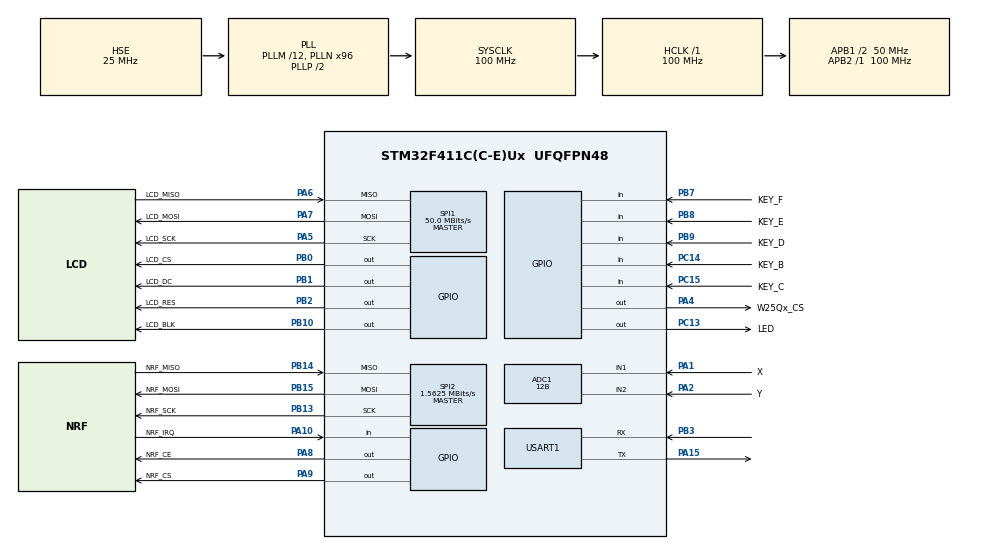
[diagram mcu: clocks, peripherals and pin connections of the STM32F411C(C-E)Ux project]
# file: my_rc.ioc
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ADC1.Channel-0\#ChannelRegularConversion=ADC_CHANNEL_1
ADC1.Channel-5\#ChannelRegularConversion=ADC_CHANNEL_2
ADC1.ClockPrescaler=ADC_CLOCK_SYNC_PCLK_DIV4
ADC1.ContinuousConvMode=ENABLE
ADC1.DMAContinuousRequests=ENABLE
ADC1.DiscontinuousConvMode=DISABLE
ADC1.NbrOfConversion=2
ADC1.NbrOfConversionFlag=1
ADC1.Rank-0\#ChannelRegularConversion=1
ADC1.Rank-5\#ChannelRegularConversion=2
ADC1.Resolution=ADC_RESOLUTION_12B
ADC1.SamplingTime-0\#ChannelRegularConversion=ADC_SAMPLETIME_3CYCLES
ADC1.SamplingTime-5\#ChannelRegularConversion=ADC_SAMPLETIME_3CYCLES
ADC1.ScanConvMode=ENABLE
ADC1.master=1
Dma.ADC1.0.Direction=DMA_PERIPH_TO_MEMORY
Dma.ADC1.0.FIFOMode=DMA_FIFOMODE_DISABLE
Dma.ADC1.0.Instance=DMA2_Stream0
Dma.ADC1.0.MemDataAlignment=DMA_MDATAALIGN_HALFWORD
Dma.ADC1.0.MemInc=DMA_MINC_ENABLE
Dma.ADC1.0.Mode=DMA_CIRCULAR
Dma.ADC1.0.PeriphDataAlignment=DMA_PDATAALIGN_HALFWORD
Dma.ADC1.0.PeriphInc=DMA_PINC_DISABLE
Dma.ADC1.0.Priority=DMA_PRIORITY_MEDIUM
Dma.Request0=ADC1
Dma.Request1=SPI1_TX
Dma.Request2=USART1_RX
Dma.Request3=USART1_TX
Dma.SPI1_TX.1.Direction=DMA_MEMORY_TO_PERIPH
Dma.SPI1_TX.1.FIFOMode=DMA_FIFOMODE_DISABLE
Dma.SPI1_TX.1.Instance=DMA2_Stream5
Dma.SPI1_TX.1.MemDataAlignment=DMA_MDATAALIGN_BYTE
Dma.SPI1_TX.1.MemInc=DMA_MINC_ENABLE
Dma.SPI1_TX.1.Mode=DMA_NORMAL
Dma.SPI1_TX.1.PeriphDataAlignment=DMA_PDATAALIGN_BYTE
Dma.SPI1_TX.1.PeriphInc=DMA_PINC_DISABLE
Dma.SPI1_TX.1.Priority=DMA_PRIORITY_MEDIUM
Dma.USART1_RX.2.Direction=DMA_PERIPH_TO_MEMORY
Dma.USART1_RX.2.FIFOMode=DMA_FIFOMODE_DISABLE
Dma.USART1_RX.2.Instance=DMA2_Stream2
Dma.USART1_RX.2.MemDataAlignment=DMA_MDATAALIGN_BYTE
Dma.USART1_RX.2.MemInc=DMA_MINC_ENABLE
Dma.USART1_RX.2.Mode=DMA_NORMAL
Dma.USART1_RX.2.PeriphDataAlignment=DMA_PDATAALIGN_BYTE
Dma.USART1_RX.2.PeriphInc=DMA_PINC_DISABLE
Dma.USART1_RX.2.Priority=DMA_PRIORITY_HIGH
Dma.USART1_TX.3.Direction=DMA_MEMORY_TO_PERIPH
Dma.USART1_TX.3.FIFOMode=DMA_FIFOMODE_DISABLE
Dma.USART1_TX.3.Instance=DMA2_Stream7
Dma.USART1_TX.3.MemDataAlignment=DMA_MDATAALIGN_BYTE
Dma.USART1_TX.3.MemInc=DMA_MINC_ENABLE
Dma.USART1_TX.3.Mode=DMA_NORMAL
Dma.USART1_TX.3.PeriphDataAlignment=DMA_PDATAALIGN_BYTE
Dma.USART1_TX.3.PeriphInc=DMA_PINC_DISABLE
Dma.USART1_TX.3.Priority=DMA_PRIORITY_MEDIUM
Mcu.Family=STM32F4
Mcu.Name=STM32F411C(C-E)Ux
Mcu.Package=UFQFPN48
NVIC.DMA2_Stream0_IRQn=true\:0\:0\:false\:false\:true\:false\:true\:true
NVIC.DMA2_Stream2_IRQn=true\:0\:0\:false\:false\:true\:false\:true\:true
NVIC.DMA2_Stream5_IRQn=true\:0\:0\:false\:false\:true\:false\:true\:true
NVIC.DMA2_Stream7_IRQn=true\:0\:0\:false\:false\:true\:false\:true\:true
NVIC.PriorityGroup=NVIC_PRIORITYGROUP_4
NVIC.TIM1_UP_TIM10_IRQn=true\:0\:0\:false\:false\:true\:true\:true\:true
NVIC.USART1_IRQn=true\:0\:0\:false\:false\:true\:true\:true\:true
PA1.GPIO_Label=X
PA1.Signal=ADCx_IN1
PA10.GPIO_Label=NRF_IRQ
PA10.GPIO_PuPd=GPIO_PULLUP
PA10.Signal=GPIO_Input
PA13.Mode=Serial_Wire
PA13.Signal=SYS_JTMS-SWDIO
PA14.Mode=Serial_Wire
PA14.Signal=SYS_JTCK-SWCLK
PA15.Mode=Asynchronous
PA15.Signal=USART1_TX
PA2.GPIO_Label=Y
PA2.Signal=ADCx_IN2
PA4.GPIO_Label=W25Qx_CS
PA4.GPIO_PuPd=GPIO_PULLUP
PA4.GPIO_Speed=GPIO_SPEED_FREQ_HIGH
PA4.PinState=GPIO_PIN_SET
PA4.Signal=GPIO_Output
PA5.GPIO_Label=LCD_SCK
PA5.Mode=Full_Duplex_Master
PA5.Signal=SPI1_SCK
PA6.GPIO_Label=LCD_MISO
PA6.Mode=Full_Duplex_Master
PA6.Signal=SPI1_MISO
PA7.GPIO_Label=LCD_MOSI
PA7.Mode=Full_Duplex_Master
PA7.Signal=SPI1_MOSI
PA8.GPIO_Label=NRF_CE
PA8.GPIO_PuPd=GPIO_PULLUP
PA8.GPIO_Speed=GPIO_SPEED_FREQ_HIGH
PA8.Signal=GPIO_Output
PA9.GPIO_Label=NRF_CS
PA9.GPIO_PuPd=GPIO_PULLUP
PA9.GPIO_Speed=GPIO_SPEED_FREQ_HIGH
PA9.PinState=GPIO_PIN_SET
PA9.Signal=GPIO_Output
PB0.GPIO_Label=LCD_CS
PB0.GPIO_PuPd=GPIO_PULLUP
PB0.GPIO_Speed=GPIO_SPEED_FREQ_VERY_HIGH
PB0.PinState=GPIO_PIN_SET
PB0.Signal=GPIO_Output
PB1.GPIO_Label=LCD_DC
PB1.GPIO_PuPd=GPIO_PULLUP
PB1.GPIO_Speed=GPIO_SPEED_FREQ_VERY_HIGH
PB1.PinState=GPIO_PIN_SET
PB1.Signal=GPIO_Output
PB10.GPIO_Label=LCD_BLK
PB10.GPIO_ModeDefaultOutputPP=GPIO_MODE_OUTPUT_PP
PB10.GPIO_PuPd=GPIO_PULLUP
PB10.GPIO_Speed=GPIO_SPEED_FREQ_HIGH
PB10.PinState=GPIO_PIN_SET
PB10.Signal=GPIO_Output
PB13.GPIO_Label=NRF_SCK
PB13.Mode=Full_Duplex_Master
PB13.Signal=SPI2_SCK
PB14.GPIO_Label=NRF_MISO
PB14.Mode=Full_Duplex_Master
PB14.Signal=SPI2_MISO
PB15.GPIO_Label=NRF_MOSI
PB15.Mode=Full_Duplex_Master
PB15.Signal=SPI2_MOSI
PB2.GPIO_Label=LCD_RES
PB2.GPIO_PuPd=GPIO_PULLUP
PB2.GPIO_Speed=GPIO_SPEED_FREQ_HIGH
PB2.PinState=GPIO_PIN_SET
PB2.Signal=GPIO_Output
PB3.Mode=Asynchronous
PB3.Signal=USART1_RX
PB7.GPIO_Label=KEY_F
PB7.Signal=GPIO_Input
PB8.GPIO_Label=KEY_E
PB8.Signal=GPIO_Input
PB9.GPIO_Label=KEY_D
PB9.Signal=GPIO_Input
PC13-ANTI_TAMP.GPIO_Label=LED
PC13-ANTI_TAMP.PinState=GPIO_PIN_SET
PC13-ANTI_TAMP.Signal=GPIO_Output
PC14-OSC32_IN.GPIO_Label=KEY_B
PC14-OSC32_IN.Signal=GPIO_Input
PC15-OSC32_OUT.GPIO_Label=KEY_C
PC15-OSC32_OUT.Signal=GPIO_Input
PH0\ -\ OSC_IN.Mode=HSE-External-Oscillator
PH0\ -\ OSC_IN.Signal=RCC_OSC_IN
PH1\ -\ OSC_OUT.Mode=HSE-External-Oscillator
PH1\ -\ OSC_OUT.Signal=RCC_OSC_OUT
ProjectManager.HeapSize=0x200
ProjectManager.StackSize=0x400
ProjectManager.TargetToolchain=MDK-ARM V5.32
RCC.48MHZClocksFreq_Value=40000000
RCC.AHBFreq_Value=100000000
RCC.APB1CLKDivider=RCC_HCLK_DIV2
RCC.APB1Freq_Value=50000000
RCC.APB1TimFreq_Value=100000000
RCC.APB2Freq_Value=100000000
RCC.APB2TimFreq_Value=100000000
RCC.CortexFreq_Value=100000000
RCC.HCLKFreq_Value=100000000
RCC.HSE_VALUE=25000000
RCC.HSI_VALUE=16000000
RCC.LSE_VALUE=32768
RCC.PLLM=12
RCC.PLLN=96
RCC.PLLQ=5
RCC.PLLSourceVirtual=RCC_PLLSOURCE_HSE
RCC.SYSCLKFreq_VALUE=100000000
RCC.SYSCLKSource=RCC_SYSCLKSOURCE_PLLCLK
RCC.VCOOutputFreq_Value=200000000
SH.ADCx_IN1.0=ADC1_IN1,IN1
SH.ADCx_IN2.0=ADC1_IN2,IN2
SPI1.BaudRatePrescaler=SPI_BAUDRATEPRESCALER_2
SPI1.CLKPhase=SPI_PHASE_2EDGE
SPI1.CLKPolarity=SPI_POLARITY_HIGH
SPI1.CalculateBaudRate=50.0 MBits/s
SPI1.DataSize=SPI_DATASIZE_8BIT
SPI1.Direction=SPI_DIRECTION_2LINES
SPI1.Mode=SPI_MODE_MASTER
SPI1.VirtualType=VM_MASTER
SPI2.BaudRatePrescaler=SPI_BAUDRATEPRESCALER_32
SPI2.CalculateBaudRate=1.5625 MBits/s
SPI2.Direction=SPI_DIRECTION_2LINES
SPI2.Mode=SPI_MODE_MASTER
SPI2.VirtualType=VM_MASTER
TIM10.Prescaler=59
USART1.VirtualMode=VM_ASYNC
VP_TIM10_VS_ClockSourceINT.Mode=Enable_Timer
board=custom

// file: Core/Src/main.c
/* USER CODE BEGIN Header */
/**
  ******************************************************************************
  * @file           : main.c
  * @brief          : Main program body
  ******************************************************************************
  * @attention
  *
  * Copyright (c) 2023 STMicroelectronics.
  * All rights reserved.
  *
  * This software is licensed under terms that can be found in the LICENSE file
  * in the root directory of this software component.
  * If no LICENSE file comes with this software, it is provided AS-IS.
  *
  ******************************************************************************
  */
/* USER CODE END Header */
#include "main.h"

/* USER CODE BEGIN Includes */
#include "system_start.h"
/* USER CODE END Includes */

void SystemClock_Config(void);
static void MX_GPIO_Init(void);
static void MX_DMA_Init(void);
static void MX_TIM10_Init(void);
static void MX_ADC1_Init(void);
static void MX_SPI1_Init(void);
static void MX_SPI2_Init(void);
static void MX_USART1_UART_Init(void);

int main(void)
{

  /* MCU Configuration--------------------------------------------------------*/

  /* Reset of all peripherals, Initializes the Flash interface and the Systick. */
  HAL_Init();

  /* Configure the system clock */
  SystemClock_Config();

  /* Initialize all configured peripherals */
  MX_GPIO_Init();
  MX_DMA_Init();
  MX_TIM10_Init();
  MX_ADC1_Init();
  MX_SPI1_Init();
  MX_SPI2_Init();
  MX_USART1_UART_Init();
  /* USER CODE BEGIN 2 */
	System_Init();
  /* USER CODE END 2 */

  /* Infinite loop */
  /* USER CODE BEGIN WHILE */
  while (1)
  {
		System_Loop();
    /* USER CODE END WHILE */

  }
}

void SystemClock_Config(void)
{
  RCC_OscInitTypeDef RCC_OscInitStruct = {0};
  RCC_ClkInitTypeDef RCC_ClkInitStruct = {0};

  /** Configure the main internal regulator output voltage
  */
  __HAL_RCC_PWR_CLK_ENABLE();
  __HAL_PWR_VOLTAGESCALING_CONFIG(PWR_REGULATOR_VOLTAGE_SCALE1);

  /** Initializes the RCC Oscillators according to the specified parameters
  * in the RCC_OscInitTypeDef structure.
  */
  RCC_OscInitStruct.OscillatorType = RCC_OSCILLATORTYPE_HSE;
  RCC_OscInitStruct.HSEState = RCC_HSE_ON;
  RCC_OscInitStruct.PLL.PLLState = RCC_PLL_ON;
  RCC_OscInitStruct.PLL.PLLSource = RCC_PLLSOURCE_HSE;
  RCC_OscInitStruct.PLL.PLLM = 12;
  RCC_OscInitStruct.PLL.PLLN = 96;
  RCC_OscInitStruct.PLL.PLLP = RCC_PLLP_DIV2;
  RCC_OscInitStruct.PLL.PLLQ = 5;
  if (HAL_RCC_OscConfig(&RCC_OscInitStruct) != HAL_OK)
  {
    Error_Handler();
  }

  /** Initializes the CPU, AHB and APB buses clocks
  */
  RCC_ClkInitStruct.ClockType = RCC_CLOCKTYPE_HCLK|RCC_CLOCKTYPE_SYSCLK
                              |RCC_CLOCKTYPE_PCLK1|RCC_CLOCKTYPE_PCLK2;
  RCC_ClkInitStruct.SYSCLKSource = RCC_SYSCLKSOURCE_PLLCLK;
  RCC_ClkInitStruct.AHBCLKDivider = RCC_SYSCLK_DIV1;
  RCC_ClkInitStruct.APB1CLKDivider = RCC_HCLK_DIV2;
  RCC_ClkInitStruct.APB2CLKDivider = RCC_HCLK_DIV1;

  if (HAL_RCC_ClockConfig(&RCC_ClkInitStruct, FLASH_LATENCY_3) != HAL_OK)
  {
    Error_Handler();
  }
}

static void MX_ADC1_Init(void)
{

  LL_ADC_InitTypeDef ADC_InitStruct = {0};
  LL_ADC_REG_InitTypeDef ADC_REG_InitStruct = {0};
  LL_ADC_CommonInitTypeDef ADC_CommonInitStruct = {0};

  LL_GPIO_InitTypeDef GPIO_InitStruct = {0};

  /* Peripheral clock enable */
  LL_APB2_GRP1_EnableClock(LL_APB2_GRP1_PERIPH_ADC1);

  LL_AHB1_GRP1_EnableClock(LL_AHB1_GRP1_PERIPH_GPIOA);
  /**ADC1 GPIO Configuration
  PA1   ------> ADC1_IN1
  PA2   ------> ADC1_IN2
  */
  GPIO_InitStruct.Pin = LL_GPIO_PIN_1|LL_GPIO_PIN_2;
  GPIO_InitStruct.Mode = LL_GPIO_MODE_ANALOG;
  GPIO_InitStruct.Pull = LL_GPIO_PULL_NO;
  LL_GPIO_Init(GPIOA, &GPIO_InitStruct);

  /* ADC1 DMA Init */

  /* ADC1 Init */
  LL_DMA_SetChannelSelection(DMA2, LL_DMA_STREAM_0, LL_DMA_CHANNEL_0);

  LL_DMA_SetDataTransferDirection(DMA2, LL_DMA_STREAM_0, LL_DMA_DIRECTION_PERIPH_TO_MEMORY);

  LL_DMA_SetStreamPriorityLevel(DMA2, LL_DMA_STREAM_0, LL_DMA_PRIORITY_MEDIUM);

  LL_DMA_SetMode(DMA2, LL_DMA_STREAM_0, LL_DMA_MODE_CIRCULAR);

  LL_DMA_SetPeriphIncMode(DMA2, LL_DMA_STREAM_0, LL_DMA_PERIPH_NOINCREMENT);

  LL_DMA_SetMemoryIncMode(DMA2, LL_DMA_STREAM_0, LL_DMA_MEMORY_INCREMENT);

  LL_DMA_SetPeriphSize(DMA2, LL_DMA_STREAM_0, LL_DMA_PDATAALIGN_HALFWORD);

  LL_DMA_SetMemorySize(DMA2, LL_DMA_STREAM_0, LL_DMA_MDATAALIGN_HALFWORD);

  LL_DMA_DisableFifoMode(DMA2, LL_DMA_STREAM_0);

  /** Common config
  */
  ADC_InitStruct.Resolution = LL_ADC_RESOLUTION_12B;
  ADC_InitStruct.DataAlignment = LL_ADC_DATA_ALIGN_RIGHT;
  ADC_InitStruct.SequencersScanMode = LL_ADC_SEQ_SCAN_ENABLE;
  LL_ADC_Init(ADC1, &ADC_InitStruct);
  ADC_REG_InitStruct.TriggerSource = LL_ADC_REG_TRIG_SOFTWARE;
  ADC_REG_InitStruct.SequencerLength = LL_ADC_REG_SEQ_SCAN_ENABLE_2RANKS;
  ADC_REG_InitStruct.SequencerDiscont = LL_ADC_REG_SEQ_DISCONT_DISABLE;
  ADC_REG_InitStruct.ContinuousMode = LL_ADC_REG_CONV_CONTINUOUS;
  ADC_REG_InitStruct.DMATransfer = LL_ADC_REG_DMA_TRANSFER_UNLIMITED;
  LL_ADC_REG_Init(ADC1, &ADC_REG_InitStruct);
  LL_ADC_REG_SetFlagEndOfConversion(ADC1, LL_ADC_REG_FLAG_EOC_UNITARY_CONV);
  ADC_CommonInitStruct.CommonClock = LL_ADC_CLOCK_SYNC_PCLK_DIV4;
  LL_ADC_CommonInit(__LL_ADC_COMMON_INSTANCE(ADC1), &ADC_CommonInitStruct);

  /** Configure Regular Channel
  */
  LL_ADC_REG_SetSequencerRanks(ADC1, LL_ADC_REG_RANK_1, LL_ADC_CHANNEL_1);
  LL_ADC_SetChannelSamplingTime(ADC1, LL_ADC_CHANNEL_1, LL_ADC_SAMPLINGTIME_3CYCLES);

  /** Configure Regular Channel
  */
  LL_ADC_REG_SetSequencerRanks(ADC1, LL_ADC_REG_RANK_2, LL_ADC_CHANNEL_2);
  LL_ADC_SetChannelSamplingTime(ADC1, LL_ADC_CHANNEL_2, LL_ADC_SAMPLINGTIME_3CYCLES);

}

static void MX_SPI1_Init(void)
{

  LL_SPI_InitTypeDef SPI_InitStruct = {0};

  LL_GPIO_InitTypeDef GPIO_InitStruct = {0};

  /* Peripheral clock enable */
  LL_APB2_GRP1_EnableClock(LL_APB2_GRP1_PERIPH_SPI1);

  LL_AHB1_GRP1_EnableClock(LL_AHB1_GRP1_PERIPH_GPIOA);
  /**SPI1 GPIO Configuration
  PA5   ------> SPI1_SCK
  PA6   ------> SPI1_MISO
  PA7   ------> SPI1_MOSI
  */
  GPIO_InitStruct.Pin = LL_GPIO_PIN_5|LL_GPIO_PIN_6|LL_GPIO_PIN_7;
  GPIO_InitStruct.Mode = LL_GPIO_MODE_ALTERNATE;
  GPIO_InitStruct.Speed = LL_GPIO_SPEED_FREQ_VERY_HIGH;
  GPIO_InitStruct.OutputType = LL_GPIO_OUTPUT_PUSHPULL;
  GPIO_InitStruct.Pull = LL_GPIO_PULL_NO;
  GPIO_InitStruct.Alternate = LL_GPIO_AF_5;
  LL_GPIO_Init(GPIOA, &GPIO_InitStruct);

  /* SPI1 DMA Init */

  /* SPI1_TX Init */
  LL_DMA_SetChannelSelection(DMA2, LL_DMA_STREAM_5, LL_DMA_CHANNEL_3);

  LL_DMA_SetDataTransferDirection(DMA2, LL_DMA_STREAM_5, LL_DMA_DIRECTION_MEMORY_TO_PERIPH);

  LL_DMA_SetStreamPriorityLevel(DMA2, LL_DMA_STREAM_5, LL_DMA_PRIORITY_MEDIUM);

  LL_DMA_SetMode(DMA2, LL_DMA_STREAM_5, LL_DMA_MODE_NORMAL);

  LL_DMA_SetPeriphIncMode(DMA2, LL_DMA_STREAM_5, LL_DMA_PERIPH_NOINCREMENT);

  LL_DMA_SetMemoryIncMode(DMA2, LL_DMA_STREAM_5, LL_DMA_MEMORY_INCREMENT);

  LL_DMA_SetPeriphSize(DMA2, LL_DMA_STREAM_5, LL_DMA_PDATAALIGN_BYTE);

  LL_DMA_SetMemorySize(DMA2, LL_DMA_STREAM_5, LL_DMA_MDATAALIGN_BYTE);

  LL_DMA_DisableFifoMode(DMA2, LL_DMA_STREAM_5);

  /* SPI1 parameter configuration*/
  SPI_InitStruct.TransferDirection = LL_SPI_FULL_DUPLEX;
  SPI_InitStruct.Mode = LL_SPI_MODE_MASTER;
  SPI_InitStruct.DataWidth = LL_SPI_DATAWIDTH_8BIT;
  SPI_InitStruct.ClockPolarity = LL_SPI_POLARITY_HIGH;
  SPI_InitStruct.ClockPhase = LL_SPI_PHASE_2EDGE;
  SPI_InitStruct.NSS = LL_SPI_NSS_SOFT;
  SPI_InitStruct.BaudRate = LL_SPI_BAUDRATEPRESCALER_DIV2;
  SPI_InitStruct.BitOrder = LL_SPI_MSB_FIRST;
  SPI_InitStruct.CRCCalculation = LL_SPI_CRCCALCULATION_DISABLE;
  SPI_InitStruct.CRCPoly = 10;
  LL_SPI_Init(SPI1, &SPI_InitStruct);
  LL_SPI_SetStandard(SPI1, LL_SPI_PROTOCOL_MOTOROLA);

}

static void MX_SPI2_Init(void)
{

  LL_SPI_InitTypeDef SPI_InitStruct = {0};

  LL_GPIO_InitTypeDef GPIO_InitStruct = {0};

  /* Peripheral clock enable */
  LL_APB1_GRP1_EnableClock(LL_APB1_GRP1_PERIPH_SPI2);

  LL_AHB1_GRP1_EnableClock(LL_AHB1_GRP1_PERIPH_GPIOB);
  /**SPI2 GPIO Configuration
  PB13   ------> SPI2_SCK
  PB14   ------> SPI2_MISO
  PB15   ------> SPI2_MOSI
  */
  GPIO_InitStruct.Pin = LL_GPIO_PIN_13|LL_GPIO_PIN_14|LL_GPIO_PIN_15;
  GPIO_InitStruct.Mode = LL_GPIO_MODE_ALTERNATE;
  GPIO_InitStruct.Speed = LL_GPIO_SPEED_FREQ_VERY_HIGH;
  GPIO_InitStruct.OutputType = LL_GPIO_OUTPUT_PUSHPULL;
  GPIO_InitStruct.Pull = LL_GPIO_PULL_NO;
  GPIO_InitStruct.Alternate = LL_GPIO_AF_5;
  LL_GPIO_Init(GPIOB, &GPIO_InitStruct);

  /* SPI2 parameter configuration*/
  SPI_InitStruct.TransferDirection = LL_SPI_FULL_DUPLEX;
  SPI_InitStruct.Mode = LL_SPI_MODE_MASTER;
  SPI_InitStruct.DataWidth = LL_SPI_DATAWIDTH_8BIT;
  SPI_InitStruct.ClockPolarity = LL_SPI_POLARITY_LOW;
  SPI_InitStruct.ClockPhase = LL_SPI_PHASE_1EDGE;
  SPI_InitStruct.NSS = LL_SPI_NSS_SOFT;
  SPI_InitStruct.BaudRate = LL_SPI_BAUDRATEPRESCALER_DIV32;
  SPI_InitStruct.BitOrder = LL_SPI_MSB_FIRST;
  SPI_InitStruct.CRCCalculation = LL_SPI_CRCCALCULATION_DISABLE;
  SPI_InitStruct.CRCPoly = 10;
  LL_SPI_Init(SPI2, &SPI_InitStruct);
  LL_SPI_SetStandard(SPI2, LL_SPI_PROTOCOL_MOTOROLA);

}

static void MX_TIM10_Init(void)
{

  LL_TIM_InitTypeDef TIM_InitStruct = {0};

  /* Peripheral clock enable */
  LL_APB2_GRP1_EnableClock(LL_APB2_GRP1_PERIPH_TIM10);

  /* TIM10 interrupt Init */
  NVIC_SetPriority(TIM1_UP_TIM10_IRQn, NVIC_EncodePriority(NVIC_GetPriorityGrouping(),0, 0));
  NVIC_EnableIRQ(TIM1_UP_TIM10_IRQn);

  TIM_InitStruct.Prescaler = 59;
  TIM_InitStruct.CounterMode = LL_TIM_COUNTERMODE_UP;
  TIM_InitStruct.Autoreload = 65535;
  TIM_InitStruct.ClockDivision = LL_TIM_CLOCKDIVISION_DIV1;
  LL_TIM_Init(TIM10, &TIM_InitStruct);
  LL_TIM_DisableARRPreload(TIM10);

}

static void MX_USART1_UART_Init(void)
{

  LL_USART_InitTypeDef USART_InitStruct = {0};

  LL_GPIO_InitTypeDef GPIO_InitStruct = {0};

  /* Peripheral clock enable */
  LL_APB2_GRP1_EnableClock(LL_APB2_GRP1_PERIPH_USART1);

  LL_AHB1_GRP1_EnableClock(LL_AHB1_GRP1_PERIPH_GPIOA);
  LL_AHB1_GRP1_EnableClock(LL_AHB1_GRP1_PERIPH_GPIOB);
  /**USART1 GPIO Configuration
  PA15   ------> USART1_TX
  PB3   ------> USART1_RX
  */
  GPIO_InitStruct.Pin = LL_GPIO_PIN_15;
  GPIO_InitStruct.Mode = LL_GPIO_MODE_ALTERNATE;
  GPIO_InitStruct.Speed = LL_GPIO_SPEED_FREQ_VERY_HIGH;
  GPIO_InitStruct.OutputType = LL_GPIO_OUTPUT_PUSHPULL;
  GPIO_InitStruct.Pull = LL_GPIO_PULL_NO;
  GPIO_InitStruct.Alternate = LL_GPIO_AF_7;
  LL_GPIO_Init(GPIOA, &GPIO_InitStruct);

  GPIO_InitStruct.Pin = LL_GPIO_PIN_3;
  GPIO_InitStruct.Mode = LL_GPIO_MODE_ALTERNATE;
  GPIO_InitStruct.Speed = LL_GPIO_SPEED_FREQ_VERY_HIGH;
  GPIO_InitStruct.OutputType = LL_GPIO_OUTPUT_PUSHPULL;
  GPIO_InitStruct.Pull = LL_GPIO_PULL_NO;
  GPIO_InitStruct.Alternate = LL_GPIO_AF_7;
  LL_GPIO_Init(GPIOB, &GPIO_InitStruct);

  /* USART1 DMA Init */

  /* USART1_RX Init */
  LL_DMA_SetChannelSelection(DMA2, LL_DMA_STREAM_2, LL_DMA_CHANNEL_4);

  LL_DMA_SetDataTransferDirection(DMA2, LL_DMA_STREAM_2, LL_DMA_DIRECTION_PERIPH_TO_MEMORY);

  LL_DMA_SetStreamPriorityLevel(DMA2, LL_DMA_STREAM_2, LL_DMA_PRIORITY_HIGH);

  LL_DMA_SetMode(DMA2, LL_DMA_STREAM_2, LL_DMA_MODE_NORMAL);

  LL_DMA_SetPeriphIncMode(DMA2, LL_DMA_STREAM_2, LL_DMA_PERIPH_NOINCREMENT);

  LL_DMA_SetMemoryIncMode(DMA2, LL_DMA_STREAM_2, LL_DMA_MEMORY_INCREMENT);

  LL_DMA_SetPeriphSize(DMA2, LL_DMA_STREAM_2, LL_DMA_PDATAALIGN_BYTE);

  LL_DMA_SetMemorySize(DMA2, LL_DMA_STREAM_2, LL_DMA_MDATAALIGN_BYTE);

  LL_DMA_DisableFifoMode(DMA2, LL_DMA_STREAM_2);

  /* USART1_TX Init */
  LL_DMA_SetChannelSelection(DMA2, LL_DMA_STREAM_7, LL_DMA_CHANNEL_4);

  LL_DMA_SetDataTransferDirection(DMA2, LL_DMA_STREAM_7, LL_DMA_DIRECTION_MEMORY_TO_PERIPH);

  LL_DMA_SetStreamPriorityLevel(DMA2, LL_DMA_STREAM_7, LL_DMA_PRIORITY_MEDIUM);

  LL_DMA_SetMode(DMA2, LL_DMA_STREAM_7, LL_DMA_MODE_NORMAL);

  LL_DMA_SetPeriphIncMode(DMA2, LL_DMA_STREAM_7, LL_DMA_PERIPH_NOINCREMENT);

  LL_DMA_SetMemoryIncMode(DMA2, LL_DMA_STREAM_7, LL_DMA_MEMORY_INCREMENT);

  LL_DMA_SetPeriphSize(DMA2, LL_DMA_STREAM_7, LL_DMA_PDATAALIGN_BYTE);

  LL_DMA_SetMemorySize(DMA2, LL_DMA_STREAM_7, LL_DMA_MDATAALIGN_BYTE);

  LL_DMA_DisableFifoMode(DMA2, LL_DMA_STREAM_7);

  /* USART1 interrupt Init */
  NVIC_SetPriority(USART1_IRQn, NVIC_EncodePriority(NVIC_GetPriorityGrouping(),0, 0));
  NVIC_EnableIRQ(USART1_IRQn);

  USART_InitStruct.BaudRate = 115200;
  USART_InitStruct.DataWidth = LL_USART_DATAWIDTH_8B;
  USART_InitStruct.StopBits = LL_USART_STOPBITS_1;
  USART_InitStruct.Parity = LL_USART_PARITY_NONE;
  USART_InitStruct.TransferDirection = LL_USART_DIRECTION_TX_RX;
  USART_InitStruct.HardwareFlowControl = LL_USART_HWCONTROL_NONE;
  USART_InitStruct.OverSampling = LL_USART_OVERSAMPLING_16;
  LL_USART_Init(USART1, &USART_InitStruct);
  LL_USART_ConfigAsyncMode(USART1);
  LL_USART_Enable(USART1);

}

static void MX_DMA_Init(void)
{

  /* Init with LL driver */
  /* DMA controller clock enable */
  LL_AHB1_GRP1_EnableClock(LL_AHB1_GRP1_PERIPH_DMA2);

  /* DMA interrupt init */
  /* DMA2_Stream0_IRQn interrupt configuration */
  NVIC_SetPriority(DMA2_Stream0_IRQn, NVIC_EncodePriority(NVIC_GetPriorityGrouping(),0, 0));
  NVIC_EnableIRQ(DMA2_Stream0_IRQn);
  /* DMA2_Stream2_IRQn interrupt configuration */
  NVIC_SetPriority(DMA2_Stream2_IRQn, NVIC_EncodePriority(NVIC_GetPriorityGrouping(),0, 0));
  NVIC_EnableIRQ(DMA2_Stream2_IRQn);
  /* DMA2_Stream5_IRQn interrupt configuration */
  NVIC_SetPriority(DMA2_Stream5_IRQn, NVIC_EncodePriority(NVIC_GetPriorityGrouping(),0, 0));
  NVIC_EnableIRQ(DMA2_Stream5_IRQn);
  /* DMA2_Stream7_IRQn interrupt configuration */
  NVIC_SetPriority(DMA2_Stream7_IRQn, NVIC_EncodePriority(NVIC_GetPriorityGrouping(),0, 0));
  NVIC_EnableIRQ(DMA2_Stream7_IRQn);

}

static void MX_GPIO_Init(void)
{
  GPIO_InitTypeDef GPIO_InitStruct = {0};

  /* GPIO Ports Clock Enable */
  __HAL_RCC_GPIOC_CLK_ENABLE();
  __HAL_RCC_GPIOH_CLK_ENABLE();
  __HAL_RCC_GPIOA_CLK_ENABLE();
  __HAL_RCC_GPIOB_CLK_ENABLE();

  /*Configure GPIO pin Output Level */
  HAL_GPIO_WritePin(LED_GPIO_Port, LED_Pin, GPIO_PIN_SET);

  /*Configure GPIO pin Output Level */
  HAL_GPIO_WritePin(GPIOA, W25Qx_CS_Pin|NRF_CS_Pin, GPIO_PIN_SET);

  /*Configure GPIO pin Output Level */
  HAL_GPIO_WritePin(GPIOB, LCD_CS_Pin|LCD_DC_Pin|LCD_RES_Pin|LCD_BLK_Pin, GPIO_PIN_SET);

  /*Configure GPIO pin Output Level */
  HAL_GPIO_WritePin(NRF_CE_GPIO_Port, NRF_CE_Pin, GPIO_PIN_RESET);

  /*Configure GPIO pin : LED_Pin */
  GPIO_InitStruct.Pin = LED_Pin;
  GPIO_InitStruct.Mode = GPIO_MODE_OUTPUT_PP;
  GPIO_InitStruct.Pull = GPIO_NOPULL;
  GPIO_InitStruct.Speed = GPIO_SPEED_FREQ_LOW;
  HAL_GPIO_Init(LED_GPIO_Port, &GPIO_InitStruct);

  /*Configure GPIO pins : KEY_B_Pin KEY_C_Pin */
  GPIO_InitStruct.Pin = KEY_B_Pin|KEY_C_Pin;
  GPIO_InitStruct.Mode = GPIO_MODE_INPUT;
  GPIO_InitStruct.Pull = GPIO_NOPULL;
  HAL_GPIO_Init(GPIOC, &GPIO_InitStruct);

  /*Configure GPIO pins : W25Qx_CS_Pin NRF_CE_Pin NRF_CS_Pin */
  GPIO_InitStruct.Pin = W25Qx_CS_Pin|NRF_CE_Pin|NRF_CS_Pin;
  GPIO_InitStruct.Mode = GPIO_MODE_OUTPUT_PP;
  GPIO_InitStruct.Pull = GPIO_PULLUP;
  GPIO_InitStruct.Speed = GPIO_SPEED_FREQ_HIGH;
  HAL_GPIO_Init(GPIOA, &GPIO_InitStruct);

  /*Configure GPIO pins : LCD_CS_Pin LCD_DC_Pin */
  GPIO_InitStruct.Pin = LCD_CS_Pin|LCD_DC_Pin;
  GPIO_InitStruct.Mode = GPIO_MODE_OUTPUT_PP;
  GPIO_InitStruct.Pull = GPIO_PULLUP;
  GPIO_InitStruct.Speed = GPIO_SPEED_FREQ_VERY_HIGH;
  HAL_GPIO_Init(GPIOB, &GPIO_InitStruct);

  /*Configure GPIO pins : LCD_RES_Pin LCD_BLK_Pin */
  GPIO_InitStruct.Pin = LCD_RES_Pin|LCD_BLK_Pin;
  GPIO_InitStruct.Mode = GPIO_MODE_OUTPUT_PP;
  GPIO_InitStruct.Pull = GPIO_PULLUP;
  GPIO_InitStruct.Speed = GPIO_SPEED_FREQ_HIGH;
  HAL_GPIO_Init(GPIOB, &GPIO_InitStruct);

  /*Configure GPIO pin : NRF_IRQ_Pin */
  GPIO_InitStruct.Pin = NRF_IRQ_Pin;
  GPIO_InitStruct.Mode = GPIO_MODE_INPUT;
  GPIO_InitStruct.Pull = GPIO_PULLUP;
  HAL_GPIO_Init(NRF_IRQ_GPIO_Port, &GPIO_InitStruct);

  /*Configure GPIO pins : KEY_F_Pin KEY_E_Pin KEY_D_Pin */
  GPIO_InitStruct.Pin = KEY_F_Pin|KEY_E_Pin|KEY_D_Pin;
  GPIO_InitStruct.Mode = GPIO_MODE_INPUT;
  GPIO_InitStruct.Pull = GPIO_NOPULL;
  HAL_GPIO_Init(GPIOB, &GPIO_InitStruct);

}

void Error_Handler(void)
{
  __disable_irq();
  while (1)
  {
  }
}
